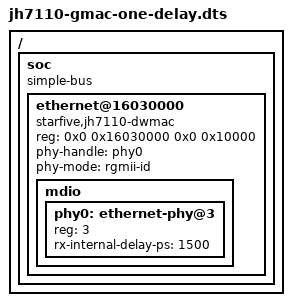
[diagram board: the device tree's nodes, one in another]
/dts-v1/;

/*
 * SYNTHETIC, not modeled on any board: a mainline-spelled gmac0 whose PHY gives a receive delay
 * and no transmit delay, at MDIO address 3. It exists so a test can show that one delay is enough
 * to read the node (the other takes OpenBSD's 1950 ps default) and that the address comes from
 * the PHY's `reg`. Compile with `dtc -I dts -O dtb -o jh7110-gmac-one-delay.dtb
 * jh7110-gmac-one-delay.dts`.
 */

/ {
	#address-cells = <2>;
	#size-cells = <2>;

	soc {
		compatible = "simple-bus";
		#address-cells = <2>;
		#size-cells = <2>;
		ranges;

		ethernet@16030000 {
			compatible = "starfive,jh7110-dwmac", "snps,dwmac-5.20";
			reg = <0x0 0x16030000 0x0 0x10000>;
			phy-handle = <&phy0>;
			phy-mode = "rgmii-id";

			mdio {
				#address-cells = <1>;
				#size-cells = <0>;

				phy0: ethernet-phy@3 {
					reg = <3>;
					rx-internal-delay-ps = <1500>;
				};
			};
		};
	};
};
